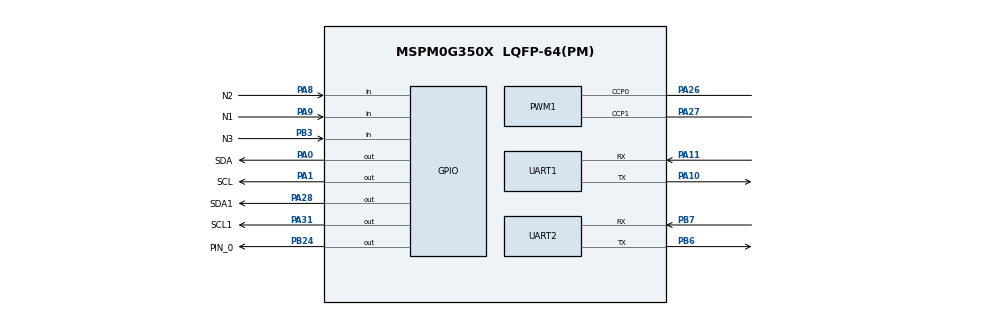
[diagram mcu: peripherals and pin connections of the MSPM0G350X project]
/**
 * @cliArgs --device "MSPM0G350X" --package "LQFP-64(PM)" --part "Default" --product "mspm0_sdk@1.30.00.03"
 * @versions {"tool":"1.19.0+3426"}
 */

/**
 * Import the modules used in this configuration.
 */
const GPIO    = scripting.addModule("/ti/driverlib/GPIO", {}, false);
const GPIO1   = GPIO.addInstance();
const GPIO2   = GPIO.addInstance();
const GPIO3   = GPIO.addInstance();
const GPIO4   = GPIO.addInstance();
const GPIO5   = GPIO.addInstance();
const GPIO6   = GPIO.addInstance();
const GPIO7   = GPIO.addInstance();
const PWM     = scripting.addModule("/ti/driverlib/PWM", {}, false);
const PWM1    = PWM.addInstance();
const SYSCTL  = scripting.addModule("/ti/driverlib/SYSCTL");
const SYSTICK = scripting.addModule("/ti/driverlib/SYSTICK");
const TIMER   = scripting.addModule("/ti/driverlib/TIMER", {}, false);
const TIMER1  = TIMER.addInstance();
const UART    = scripting.addModule("/ti/driverlib/UART", {}, false);
const UART1   = UART.addInstance();
const UART2   = UART.addInstance();

/**
 * Write custom configuration values to the imported modules.
 */
const gate7  = system.clockTree["MFCLKGATE"];
gate7.enable = true;

GPIO1.$name                              = "LED1";
GPIO1.port                               = "PORTA";
GPIO1.associatedPins[0].$name            = "PIN_14";
GPIO1.associatedPins[0].internalResistor = "PULL_DOWN";
GPIO1.associatedPins[0].assignedPin      = "14";

const Board = scripting.addModule("/ti/driverlib/Board", {}, false);

GPIO2.port                           = "PORTA";
GPIO2.$name                          = "I2C";
GPIO2.associatedPins.create(2);
GPIO2.associatedPins[0].$name        = "SCL";
GPIO2.associatedPins[0].initialValue = "SET";
GPIO2.associatedPins[0].assignedPin  = "1";
GPIO2.associatedPins[0].pin.$assign  = "PA1";
GPIO2.associatedPins[1].$name        = "SDA";
GPIO2.associatedPins[1].initialValue = "SET";
GPIO2.associatedPins[1].assignedPin  = "0";
GPIO2.associatedPins[1].pin.$assign  = "PA0";

GPIO3.$name                         = "MOTOR_GPIO";
GPIO3.port                          = "PORTA";
GPIO3.associatedPins.create(2);
GPIO3.associatedPins[0].$name       = "PIN_0_L";
GPIO3.associatedPins[0].assignedPin = "24";
GPIO3.associatedPins[1].$name       = "PIN_1_R";
GPIO3.associatedPins[1].assignedPin = "25";

GPIO4.$name                          = "OLED";
GPIO4.port                           = "PORTA";
GPIO4.associatedPins.create(2);
GPIO4.associatedPins[0].$name        = "SCL1";
GPIO4.associatedPins[0].initialValue = "SET";
GPIO4.associatedPins[0].assignedPin  = "31";
GPIO4.associatedPins[0].pin.$assign  = "PA31";
GPIO4.associatedPins[1].$name        = "SDA1";
GPIO4.associatedPins[1].initialValue = "SET";
GPIO4.associatedPins[1].assignedPin  = "28";
GPIO4.associatedPins[1].pin.$assign  = "PA28";

GPIO5.$name                              = "KEY";
GPIO5.associatedPins.create(3);
GPIO5.associatedPins[0].$name            = "N1";
GPIO5.associatedPins[0].initialValue     = "SET";
GPIO5.associatedPins[0].assignedPort     = "PORTA";
GPIO5.associatedPins[0].assignedPin      = "9";
GPIO5.associatedPins[0].direction        = "INPUT";
GPIO5.associatedPins[0].internalResistor = "PULL_UP";
GPIO5.associatedPins[0].pin.$assign      = "PA9";
GPIO5.associatedPins[1].$name            = "N2";
GPIO5.associatedPins[1].direction        = "INPUT";
GPIO5.associatedPins[1].assignedPort     = "PORTA";
GPIO5.associatedPins[1].assignedPin      = "8";
GPIO5.associatedPins[1].internalResistor = "PULL_UP";
GPIO5.associatedPins[1].pin.$assign      = "PA8";
GPIO5.associatedPins[2].$name            = "N3";
GPIO5.associatedPins[2].direction        = "INPUT";
GPIO5.associatedPins[2].assignedPort     = "PORTB";
GPIO5.associatedPins[2].assignedPin      = "3";
GPIO5.associatedPins[2].internalResistor = "PULL_UP";
GPIO5.associatedPins[2].pin.$assign      = "PB3";

GPIO6.$name                          = "BUZZER";
GPIO6.associatedPins[0].$name        = "PIN_0";
GPIO6.associatedPins[0].assignedPort = "PORTB";
GPIO6.associatedPins[0].assignedPin  = "24";
GPIO6.associatedPins[0].pin.$assign  = "PB24";

GPIO7.$name                              = "M0_SLAVE";
GPIO7.port                               = "PORTA";
GPIO7.associatedPins[0].$name            = "RST";
GPIO7.associatedPins[0].initialValue     = "SET";
GPIO7.associatedPins[0].assignedPin      = "18";
GPIO7.associatedPins[0].internalResistor = "PULL_UP";

PWM1.$name                      = "PWM_0";
PWM1.clockSource                = "MFCLK";
PWM1.peripheral.$assign         = "TIMG7";
PWM1.peripheral.ccp0Pin.$assign = "PA26";
PWM1.peripheral.ccp1Pin.$assign = "PA27";
PWM1.PWM_CHANNEL_0.$name        = "ti_driverlib_pwm_PWMTimerCC0";
PWM1.PWM_CHANNEL_0.invert       = true;
PWM1.PWM_CHANNEL_1.$name        = "ti_driverlib_pwm_PWMTimerCC1";
PWM1.PWM_CHANNEL_1.invert       = true;
PWM1.ccp0PinConfig.$name        = "ti_driverlib_gpio_GPIOPinGeneric4";
PWM1.ccp0PinConfig.enableConfig = true;
PWM1.ccp1PinConfig.$name        = "ti_driverlib_gpio_GPIOPinGeneric5";
PWM1.ccp1PinConfig.enableConfig = true;

SYSCTL.forceDefaultClkConfig = true;
SYSCTL.clockTreeEn           = true;

SYSTICK.periodEnable      = true;
SYSTICK.systickEnable     = true;
SYSTICK.interruptEnable   = true;
SYSTICK.period            = 32000;
SYSTICK.interruptPriority = "3";

TIMER1.$name            = "TIMER_0";
TIMER1.timerClkSrc      = "MFCLK";
TIMER1.timerClkDiv      = 8;
TIMER1.timerClkPrescale = 100;
TIMER1.timerPeriod      = "100 ms";
TIMER1.interrupts       = ["CC0_DN"];

UART1.$name                    = "UART_0";
UART1.uartClkSrc               = "MFCLK";
UART1.enabledInterrupts        = ["RX"];
UART1.targetBaudRate           = 115200;
UART1.peripheral.$assign       = "UART0";
UART1.peripheral.rxPin.$assign = "PA11";
UART1.peripheral.txPin.$assign = "PA10";
UART1.txPinConfig.$name        = "ti_driverlib_gpio_GPIOPinGeneric0";
UART1.rxPinConfig.$name        = "ti_driverlib_gpio_GPIOPinGeneric1";

UART2.$name                             = "UART_1";
UART2.uartClkSrc                        = "MFCLK";
UART2.targetBaudRate                    = 115200;
UART2.enableFIFO                        = true;
UART2.rxFifoThreshold                   = "DL_UART_RX_FIFO_LEVEL_3_4_FULL";
UART2.txFifoThreshold                   = "DL_UART_TX_FIFO_LEVEL_3_4_EMPTY";
UART2.enabledInterrupts                 = ["DMA_DONE_RX"];
UART2.enabledDMARXTriggers              = "DL_UART_DMA_INTERRUPT_RX";
UART2.peripheral.$assign                = "UART1";
UART2.peripheral.rxPin.$assign          = "PB7";
UART2.peripheral.txPin.$assign          = "PB6";
UART2.txPinConfig.$name                 = "ti_driverlib_gpio_GPIOPinGeneric2";
UART2.rxPinConfig.$name                 = "ti_driverlib_gpio_GPIOPinGeneric3";
UART2.DMA_CHANNEL_RX.$name              = "DMA_CH1";
UART2.DMA_CHANNEL_RX.addressMode        = "f2b";
UART2.DMA_CHANNEL_RX.srcLength          = "BYTE";
UART2.DMA_CHANNEL_RX.dstLength          = "BYTE";
UART2.DMA_CHANNEL_RX.transferMode       = "FULL_CH_REPEAT_SINGLE";
UART2.DMA_CHANNEL_RX.peripheral.$assign = "DMA_CH1";

/**
 * Pinmux solution for unlocked pins/peripherals. This ensures that minor changes to the automatic solver in a future
 * version of the tool will not impact the pinmux you originally saw.  These lines can be completely deleted in order to
 * re-solve from scratch.
 */
GPIO1.associatedPins[0].pin.$suggestSolution = "PA14";
Board.peripheral.$suggestSolution            = "DEBUGSS";
Board.peripheral.swclkPin.$suggestSolution   = "PA20";
Board.peripheral.swdioPin.$suggestSolution   = "PA19";
GPIO3.associatedPins[0].pin.$suggestSolution = "PA24";
GPIO3.associatedPins[1].pin.$suggestSolution = "PA25";
GPIO7.associatedPins[0].pin.$suggestSolution = "PA18";
TIMER1.peripheral.$suggestSolution           = "TIMA0";
